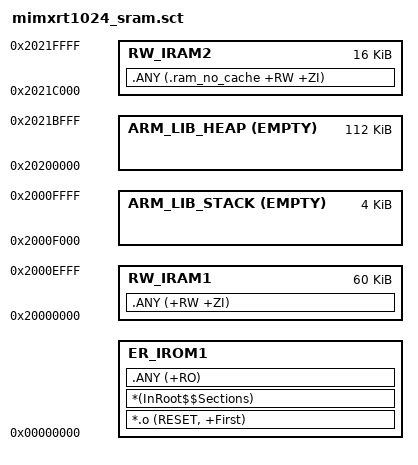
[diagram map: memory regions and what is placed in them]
;*********************************************************************
;* i.MX RT1024 linker scatter file (running code from internal SRAM) *
;*********************************************************************

LR_IROM1 0x00000000 0x10000
{
   ER_IROM1 0x00000000
   {
      *.o (RESET, +First)
      *(InRoot$$Sections)
      .ANY (+RO)
   }
   
   RW_IRAM1 0x20000000 0xF000
   {
      .ANY (+RW +ZI)
   }
   
   ARM_LIB_STACK 0x20010000 EMPTY -0x1000
   {
   }
   
   ARM_LIB_HEAP 0x20200000 EMPTY 0x1C000
   {
   }
   
   RW_IRAM2 0x2021C000 0x4000
   {
      .ANY (.ram_no_cache +RW +ZI)
   }
}
